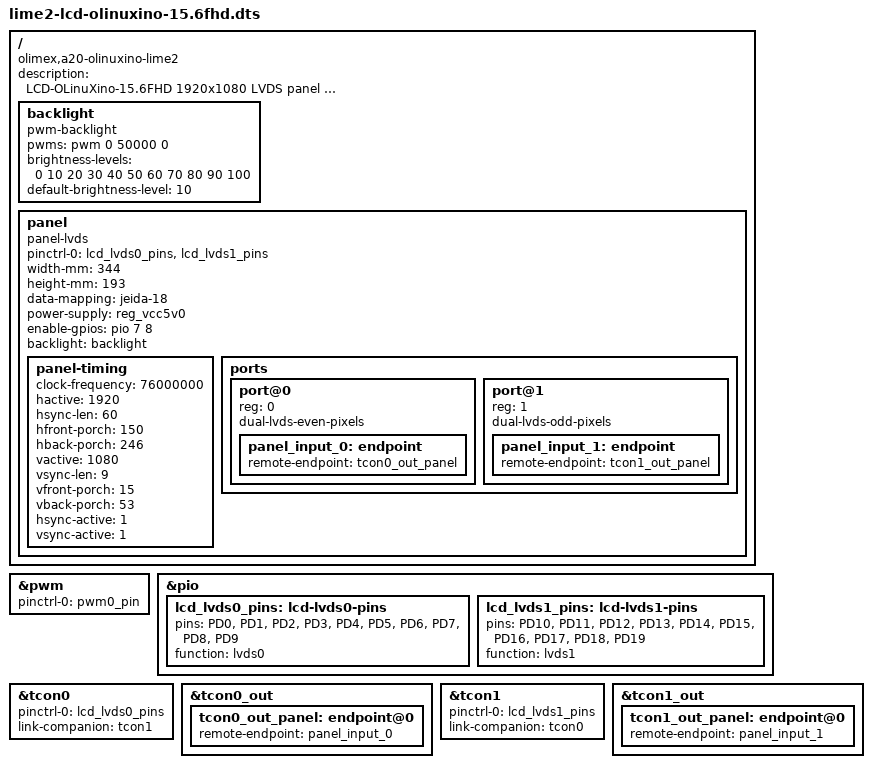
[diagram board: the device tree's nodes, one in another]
/dts-v1/;
/plugin/;

/ {
	compatible = "olimex,a20-olinuxino-lime2",
		     "olimex,a20-olinuxino-lime2-emmc";
	description = "LCD-OLinuXino-15.6FHD 1920x1080 LVDS panel without TS";

	fragment@0 {
		target-path = "/";
		__overlay__ {
			backlight: backlight {
				compatible = "pwm-backlight";
				pwms = <&pwm 0 50000 0>;
				brightness-levels = <0 10 20 30 40 50 60 70 80 90 100>;
				default-brightness-level = <10>;
			};

			panel {
				compatible = "panel-lvds";

				pinctrl-names = "default";
				pinctrl-0 = <&lcd_lvds0_pins>,
					    <&lcd_lvds1_pins>;

				width-mm = <344>;
				height-mm = <193>;
				data-mapping = "jeida-18";
				status = "okay";

				power-supply = <&reg_vcc5v0>;

				enable-gpios = <&pio 7 8 0>;
				backlight = <&backlight>;

				panel-timing {
					clock-frequency = <76000000>;
					hactive = <1920>;
					hsync-len = <60>;
					hfront-porch = <150>;
					hback-porch = <246>;
					vactive = <1080>;
					vsync-len = <9>;
					vfront-porch = <15>;
					vback-porch = <53>;

					hsync-active = <1>;
					vsync-active = <1>;
				};

			/*	port {
					panel_in_tcon0: endpoint {
						remote-endpoint = <&tcon0_out_panel>;
						allwinner,lvds-dual-link;
					};
				};*/
		    	       ports {
					#address-cells = <1>;
					#size-cells = <0>;

					port@0 {
						reg = <0>;
						dual-lvds-even-pixels;

						panel_input_0: endpoint {
							remote-endpoint = <&tcon0_out_panel>;
						};
					};

					port@1 {
						reg = <1>;
						dual-lvds-odd-pixels;

						panel_input_1: endpoint {
							remote-endpoint = <&tcon1_out_panel>;
						};
					};
				};
			};
		};
	};

	fragment@1 {
		target = <&pwm>;
		__overlay__ {
			pinctrl-names = "default";
			pinctrl-0 = <&pwm0_pin>;
			status = "okay";
		};
	};

	fragment@2 {
		target = <&pio>;
		__overlay__ {
			lcd_lvds0_pins: lcd-lvds0-pins {
				pins = "PD0", "PD1", "PD2", "PD3", "PD4",
				       "PD5", "PD6", "PD7", "PD8", "PD9";
				function = "lvds0";
			};

			lcd_lvds1_pins: lcd-lvds1-pins {
				pins = "PD10", "PD11", "PD12", "PD13", "PD14",
				       "PD15", "PD16", "PD17", "PD18", "PD19";
				function = "lvds1";
			};
		};
	};

	fragment@3 {
		target = <&tcon0>;
		__overlay__{
			pinctrl-names = "default";
			pinctrl-0 = <&lcd_lvds0_pins>;
			link-companion = <&tcon1>;
			status = "okay";
		};		

	};

	fragment@4 {
		target = <&tcon0_out>;
		__overlay__ {
			tcon0_out_panel: endpoint@0 {
				remote-endpoint = <&panel_input_0>;
			};
		};
	};

	fragment@5 {
                target = <&tcon1>;              
                __overlay__{
                        pinctrl-names = "default";
                        pinctrl-0 = <&lcd_lvds1_pins>;
                        link-companion = <&tcon0>;
                        status = "okay";
                };

        };
	
	fragment@6 {
                target = <&tcon1_out>;
                __overlay__ {
                        tcon1_out_panel: endpoint@0 {
                                remote-endpoint = <&panel_input_1>;
                        };
                };
        };


};
